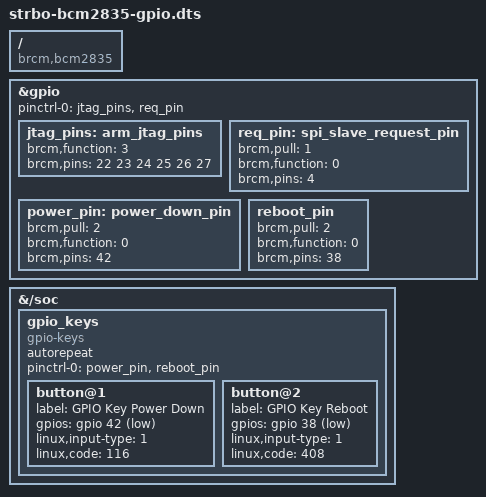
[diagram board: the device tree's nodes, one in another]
/dts-v1/;
/plugin/;

/ {
	compatible = "brcm,bcm2835";

	fragment@0 {
		target = <&gpio>;

		__overlay__ {
			pinctrl-names = "default";
			pinctrl-0 = <&jtag_pins &req_pin>;
		};
	};

	fragment@1 {
		target = <&gpio>;

		__overlay__ {
			/* Configure JTAG pins */
			jtag_pins: arm_jtag_pins {
				brcm,function = <3>;  /* alt4 */
				brcm,pins = <22 23 24 25 26 27>;
			};

			/* Enable pulldown resistor on SPI request GPIO */
			req_pin: spi_slave_request_pin {
				brcm,pull = <1>;
				brcm,function = <0>;
				brcm,pins = <4>;
			};

			/* Pin for requesting power down */
			power_pin: power_down_pin {
				brcm,pull = <2>;
				brcm,function = <0>;
				brcm,pins = <42>;
			};

			/* Pin for requesting system reset */
			reboot_pin: reboot_pin {
				brcm,pull = <2>;
				brcm,function = <0>;
				brcm,pins = <38>;
			};
		};
	};

	fragment@2 {
		target-path = "/soc";

		__overlay__ {
			gpio_keys {
				compatible = "gpio-keys";
				autorepeat;

				pinctrl-names = "default";
				pinctrl-0 = <&power_pin &reboot_pin>;
				status = "okay";

				button@1 {
					label = "GPIO Key Power Down";
					gpios = <&gpio 42 1>;
					linux,input-type = <1>;  /* EV_KEY */
					linux,code = <116>;      /* KEY_POWER */
				};

				button@2 {
					label = "GPIO Key Reboot";
					gpios = <&gpio 38 1>;
					linux,input-type = <1>;  /* EV_KEY */
					linux,code = <408>;      /* KEY_RESTART */
				};
			};
		};
	};
};
